# rCSL_usb_ohci_001 register map
Vendor: Texas Instruments
Peripheral module from a debugger description file (folder OMAPL138_C6748).
Registers are 32-bit, access per field, reset 0x0 unless marked. A register's access mark holds for its fields unless they carry their own. Offsets are as the file gives them; lines under a group give offsets from that group; [hi:lo] are bit positions; {n}, {i} and the like mark numbered series; 'fields as' and 'values as' point back to an identical list; <NAME> marks a mode.

## ohci
0x00 REVID ro reset 0x16 — Host Controller Revision Register
  [31:0] REV — Read Only BCD Representation of OpenHCI Specification Implemented by this Host Controller.
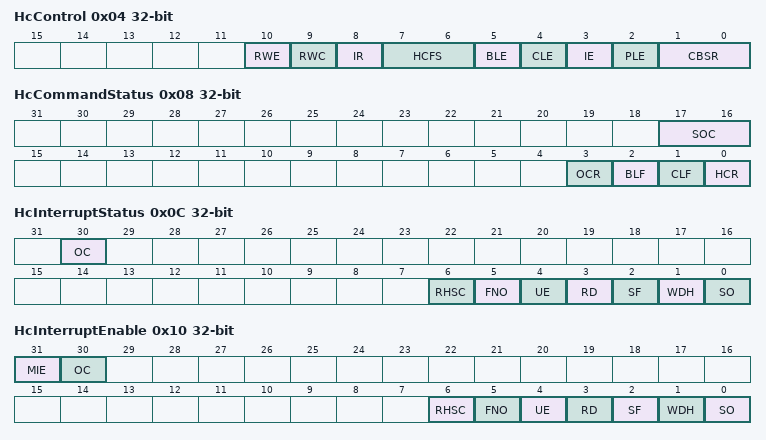
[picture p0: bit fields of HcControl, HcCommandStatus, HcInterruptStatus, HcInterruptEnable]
0x04 HcControl access not given — Determines operating mode of the Host Controller
  [10] RWE rw — Remote Wakeup Enable
    1=ENABLE (Enable Remote Wake Up Interrupt); 0=DISABLE (Disable Remote Wake Up Interrupt)
  [9] RWC rw — Remote Wakeup Connected
    1=ENABLE (HC Supports remote wakeup signaling); 0=DISABLE (HC Does not support remote wakeup signaling)
  [8] IR — Interrupt Routing (access 0)
    1=SMINT (Interrupts are routed to the System Management Interrupt); 0=HOSTINT (Interrupts are routed to the host interrupt.)
  [7:6] HCFS rw — Host Controller Functional State
    0=USBRESET (Enter USB Reset State); 1=USBRESUME (Enter USBRESUME State); 2=USBOPERATIONAL (Enter USBOPERATIONAL State); 3=USBSUSPEND (Enter USBSUSPEND State)
  [5] BLE rw — BulkListEnable
    1=ENABLE (Enable Processing of the Bulk List); 0=DISABLE (Disable Processing of the Bulk List)
  [4] CLE rw — Control List Enable
    1=ENABLE (Enable Processing of the Control List); 0=DISABLE (Disable Processing of the Control List)
  [3] IE rw — Isochronous Enable
    values as CLE
  [2] PLE rw — Periodic List Enable
    1=ENABLE (Enable Processing of the Periodic List); 0=DISABLE (Disable Processing of the Periodic List)
  [1:0] CBSR rw — Control Bulk Service Ratio
    0=RATIO11 (1:1 Ratio - Control versus Bulk); 1=RATIO21 (2:1 Ratio - Control versus Bulk); 2=RATIO31 (3:1 Ratio - Control versus Bulk); 3=RATIO41 (4:1 Ratio - Control versus Bulk)
0x08 HcCommandStatus — This register is used by the host controller to receive commands issued by the Host Controller Driver, as well as reflecting the current state of the Host Controller.
  [17:16] SOC ro — SchedulingOverrunCount
  [3] OCR rw — OwnershipChangeRequest
  [2] BLF rw — BulkListFilled
    1=SET (Set ControlListFilled); 0=CLEAR (Clear ControlListFilled)
  [1] CLF rw — ControlListFilled
    values as BLF
  [0] HCR rw — HostControllerReset
    1=SET (Assert HC Reset); 0=CLEAR (Release HC Reset)
0x0C HcInterruptStatus — This register provides status on various events that cause hardware interrupts. The host controller driver may clear specific bits by writing a '1' to them.
  [30] OC rw — OwnershipChange
  [6] RHSC rw — RootHubStatusChange
  [5] FNO rw — FrameNumberOverflow
  [4] UE rw — UnrecoverableError
  [3] RD rw — ResumeDetected
  [2] SF rw — StartofFrame
  [1] WDH rw — WritebackDoneHead
  [0] SO rw — SchedulingOverrun
0x10 HcInterruptEnable — Enable Bits for HC Interrupts
  [31] MIE rw — Master Interrupt Enable
    0=IGNORE (Write of 0 is ignored); 1=ENABLE (Write 1 to Enable)
  [30] OC rw — Ownership Change Interrupt Enable
    values as MIE
  [6] RHSC rw — Root Hub Status Change Interrupt Enable
    values as MIE
  [5] FNO rw — FrameNumberOverflow Interrupt Enable
    values as MIE
  [4] UE rw — Unrecoverable Error Interrupt Enable
    values as MIE
  [3] RD rw — ResumeDetect Interrupt Enable
    values as MIE
  [2] SF rw — StartofFrame Interrupt Enable
    values as MIE
  [1] WDH rw — HcDoneHead Writeback Interrupt Enable
    values as MIE
  [0] SO rw — Scheduling Overrun Interrupt Enable
    0=IGNORE (Write of 0 is ignored); 1=ENABLE (Write 1 to Disable)
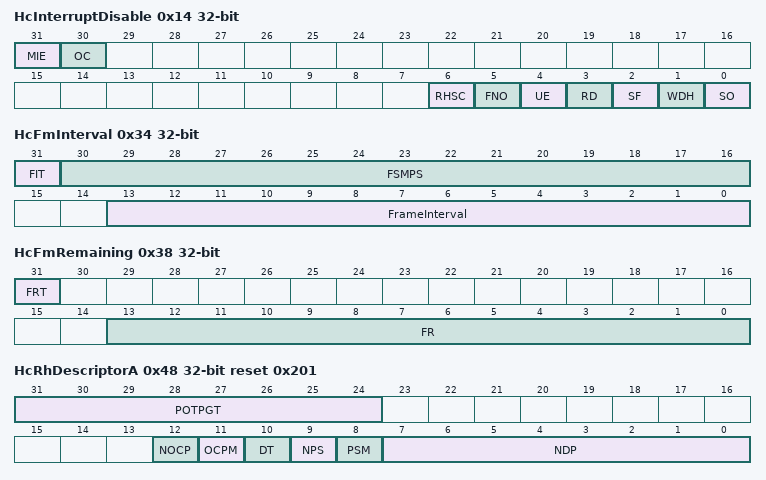
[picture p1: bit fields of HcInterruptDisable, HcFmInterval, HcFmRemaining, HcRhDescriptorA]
0x14 HcInterruptDisable — Disable bits for HC Interrupts
  [31] MIE rw — Master Interrupt Disable
    0=IGNORE (Write of 0 is ignored); 1=DISABLE (Write 1 to Disable)
  [30] OC rw — Ownership Change Interrupt Disable
    values as MIE
  [6] RHSC rw — Root Hub Status Change Interrupt Disable
    0=IGNORE (Write of 0 is ignored); 1=DISABLE (Write 1 to Enable)
  [5] FNO rw — FrameNumberOverflow Interrupt Disable
    values as MIE
  [4] UE rw — Unrecoverable Error Interrupt Disable
    values as MIE
  [3] RD rw — ResumeDetect Interrupt Disable
    values as MIE
  [2] SF rw — StartofFrame Interrupt Disable
    values as MIE
  [1] WDH rw — HcDoneHead Writeback Interrupt Disable
    values as MIE
  [0] SO rw — Scheduling Overrun Interrupt Disable
    values as MIE
0x18 HcHCCA — The HcHCCA register contains the physical address of the Host Controller Communication Area
  [31:8] HCCA rw — Base Address of HCCA
0x1C HcPeriodCurrentED ro — The HcPeriodCurrentED register contains the physical address of the current Isochronous or Interrupt Endpoint Descriptor
  [31:4] PCED — PeriodCurrentED
0x20 HcControlHeadED
  [31:4] CHED rw — ControlHeadED
0x24 HcControlCurrentED
  [31:4] CCED rw — ControlCurrentED
0x28 HcBulkHeadED ro
  [31:4] BHED — BulkHeadED
0x2C HcBulkCurrentED
  [31:4] BCED rw — BulkCurrentED
0x30 HcDoneHead ro — HcDoneHead register contains the physical address of the last completed Transfer Descriptor that was added to the Done Queue.
  [31:4] DH — DoneHead
0x34 HcFmInterval (reset mask 0xFFFFC000)
  [31] FIT rw — Frame Interval Toggle
  [30:16] FSMPS rw — FSLargestDataPacket
  [13:0] FrameInterval rw
0x38 HcFmRemaining ro
  [31] FRT — FrameRemainingToggle
  [13:0] FR — FrameRemaining
0x3C HcFmNumber ro
  [15:0] FN — FrameNumber
0x40 HcPeriodicStart
  [13:0] PS rw — PeriodicStart
0x44 HcLSThreshold (reset mask 0xFFFFF000)
  [11:0] LST rw — LSThreshold
0x48 HcRhDescriptorA reset 0x201
  [31:24] POTPGT rw — PowerOnToPowerGoodTime
  [12] NOCP rw — NoOverCurrentProtection
    0=ENABLE (Over current status is reported for ports either on a global or per port basis as determined by the value of the OCPM field.); 1=DISABLE (Over current reporting is disabled.)
  [11] OCPM rw — OverCurrentProtectionMode
    0=GLOBAL (Over current status is reported collectively for all downstream ports); 1=PERPORT (over current status is reported on a per-port basis.)
  [10] DT ro — DeviceType
  [9] NPS rw — NoPowerSwitching
    1=ALWAYSON (Ports are always powered on when the HC is powered on.); 0=SWITCHED (Ports are power switched)
  [8] PSM rw — PowerSwitchingMode
    0=GLOBAL (Downstream ports are powered as a Group); 1=PERPORT (Down stream ports are powered individually)
  [7:0] NDP ro — NumberofDownstreamPorts
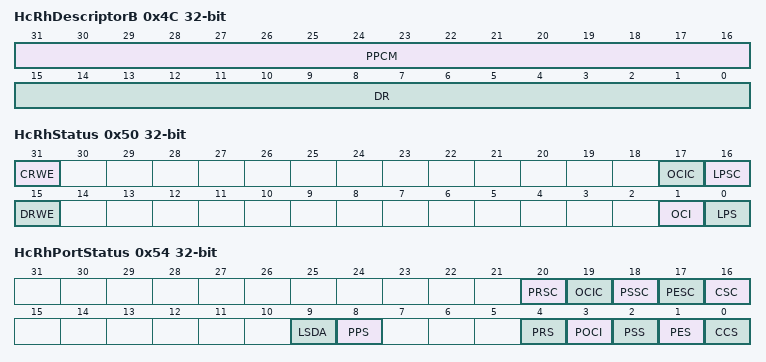
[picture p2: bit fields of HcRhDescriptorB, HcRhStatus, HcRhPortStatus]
0x4C HcRhDescriptorB rw
  [31:16] PPCM — PortPowerControlMask
    1=P1GPENA (Set Ganged Power Mask on Port 1); 0=P1GPDIS (Clear Ganged Power Mask on Port 1)
  [15:0] DR — DeviceRemovable
    0=P1DR (Port 1 Device is Removable); 1=P1DNR (Port 1 Device is Not Removable)
0x50 HcRhStatus
  [31] CRWE wo — ClearRemoteWakeupEnable
    1=CLEAR (Clears DeviceRemoteWakeupEnable); 0=NOEFFECT (No effect on DeviceRemoteWakeupEnable)
  [17] OCIC rw — OverCurrentIndicatorChange
    1=CLEAR (Clears OCI); 0=NOEFFECT (No effect on OCI)
  [16] LPSC rw — LocalPowerStatusChange
    1=POWERON (Turns port power on (to either all or selected ports)); 0=NOEFFECT (Writing 0 has no effect.)
  [15] DRWE rw — DeviceRemoteWakeupEnable
    1=SETDRWE (Writing '1' Sets Device Remove Wakeup Enable.); 0=NOEFFECT (Writing 0 has no effect.)
  [1] OCI ro — OverCurrentIndicator
  [0] LPS rw — LocalPowerStatus
    1=POWEROFF (Turns port power off (to either all or selected ports)); 0=NOEFFECT (Writing 0 has no effect.)
0x54 HcRhPortStatus
  [20] PRSC rw — PortResetStatusChange
    1=PRSCCLR (Write '1' to clear PortResetStatusChange); 0=NOEFFECT (Writing '0' has no effect.)
  [19] OCIC rw — PortOverCurrentChangeIndicator
    1=OCICCLR (Write '1' to clear OverCurrentIndicatorChange); 0=NOEFFECT (Writing '0' has no effect.)
  [18] PSSC rw — PortSuspendStatusChange
    1=PSSCCLR (Write '1' to clear PortSuspendStatusChange); 0=NOEFFECT (Writing '0' has no effect.)
  [17] PESC rw — PortEnableStatusChange
    1=PESCCLR (Write '1' to clear PortEnableStatusChange); 0=NOEFFECT (Writing '0' has no effect.)
  [16] CSC rw — ConnectStatusChange
    1=CSCCLR (Write '1' to clear CurrentConnectStatus); 0=NOEFFECT (Writing '0' has no effect.)
  [9] LSDA rw — LowSpeedDeviceAttached
    1=PPSCLR (Write '1' to clear PortPowerStatus); 0=NOEFFECT (Writing '0' has no effect.)
  [8] PPS rw — PortPowerStatus
    1=PPSSET (Write '1' to set PortPowerStatus); 0=NOEFFECT (Writing '0' has no effect.)
  [4] PRS rw — PortResetStatus
    1=PORTRESET (Write '1' to initiate a port reset); 0=NOEFFECT (Writing '0' has no effect.)
  [3] POCI rw — PortOverCurrentIndicator
    1=RESUME (Write '1' to initiate a port resume); 0=NOEFFECT (Writing '0' has no effect.)
  [2] PSS rw — PortSuspendStatus
    1=SUSPEND (Write '1' to set PortSuspendStatus); 0=NOEFFECT (Writing '0' has no effect.)
  [1] PES rw — PortEnableStatus
    1=PENA (Write '1' to set PortEnableStatus); 0=NOEFFECT (Writing '0' has no effect.)
  [0] CCS rw — CurrentConnectStatus
    0=NOEFFECT (Writing 0 has no effect.); 1=CLEAR (Clear PortEnableStatus)
